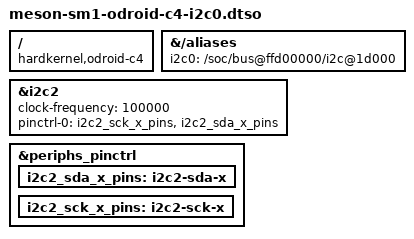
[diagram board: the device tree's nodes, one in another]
/dts-v1/;
/plugin/;

/ {
	compatible = "hardkernel,odroid-c4", "amlogic,sm1";

	fragment@0 {
		target-path = "/aliases";
		__overlay__ {
			i2c0 = "/soc/bus@ffd00000/i2c@1d000";
		};
	};

	fragment@1 {
		target = <&i2c2>;
		__overlay__ {
			status = "okay";
			clock-frequency = <100000>;
			pinctrl-0 = <&i2c2_sck_x_pins &i2c2_sda_x_pins>;
			pinctrl-names = "default";
		};
	};

	fragment@2 {
		target = <&periphs_pinctrl>;
		__overlay__ {
			i2c2_sda_x_pins: i2c2-sda-x { };
			i2c2_sck_x_pins: i2c2-sck-x { };
		};
	};

};
